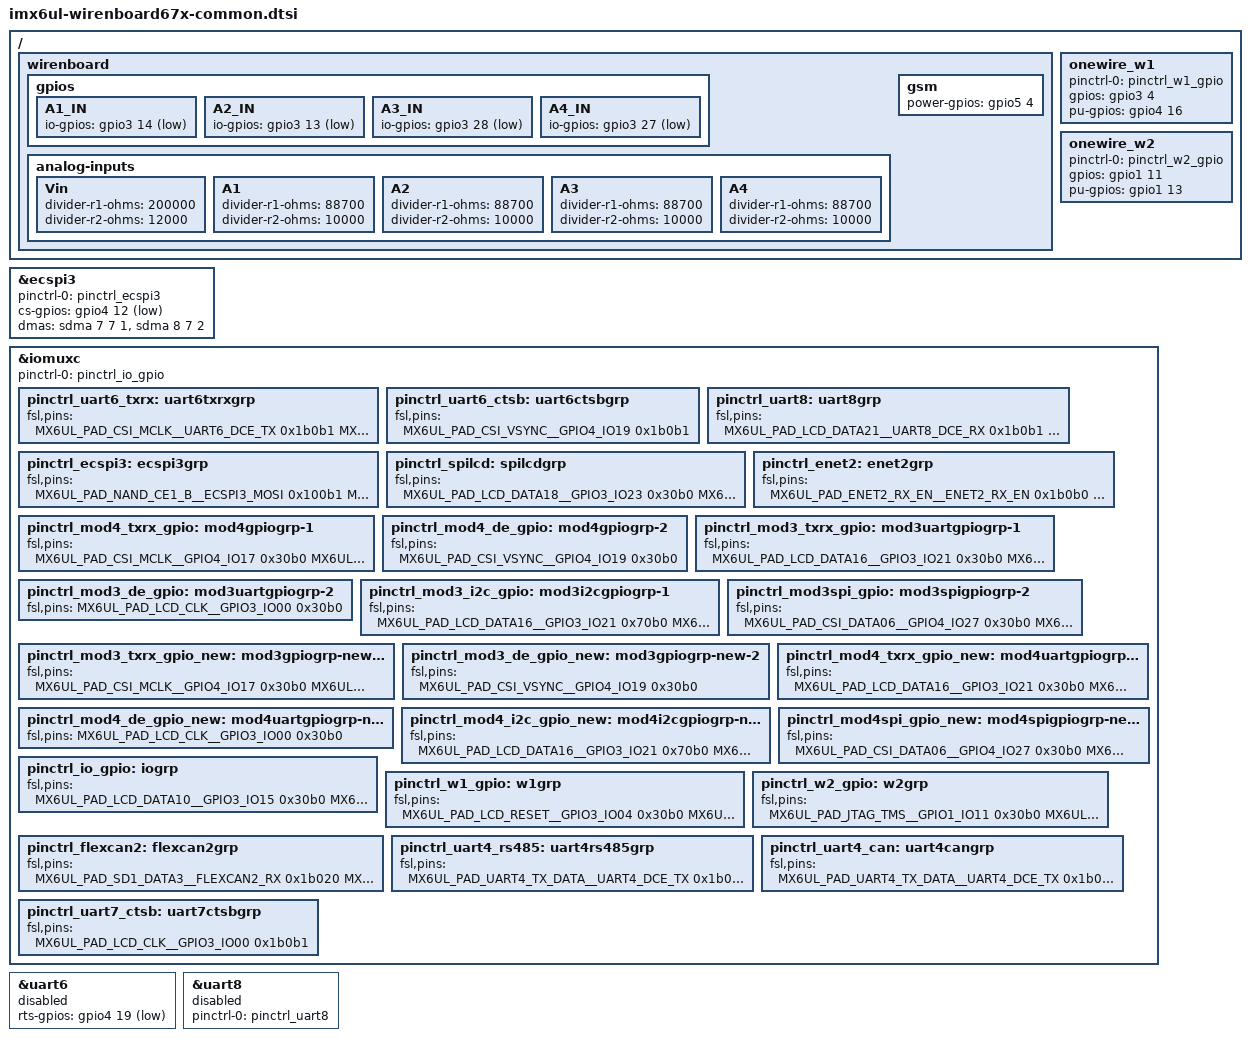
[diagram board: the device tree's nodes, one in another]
/*
 * Copyright 2020 Contactless Devices, LLC.
 *
 * The code contained herein is licensed under the GNU General Public
 * License. You may obtain a copy of the GNU General Public License
 * Version 2 or later at the following locations:
 *
 * http://www.opensource.org/licenses/gpl-license.html
 * http://www.gnu.org/copyleft/gpl.html
 */

#include "imx6ul-wirenboard6-common.dtsi"

/ {
	wirenboard {
			gpios {
				A1_IN {
					io-gpios = <&gpio3 14 1>; /* inverted */
				};

				A2_IN {
					io-gpios = <&gpio3 13 1>; /* inverted */
				};

				A3_IN {
					io-gpios = <&gpio3 28 1>; /* inverted */
				};

				A4_IN {
					io-gpios = <&gpio3 27 1>; /* inverted */
				};
			};

			analog-inputs {
				Vin {
					divider-r1-ohms = <200000>;
					divider-r2-ohms = <12000>;
				};

				A1 {
					divider-r1-ohms = <88700>;
					divider-r2-ohms = <10000>;
				};

				A2 {
					divider-r1-ohms = <88700>;
					divider-r2-ohms = <10000>;
				};

				A3 {
					divider-r1-ohms = <88700>;
					divider-r2-ohms = <10000>;
				};

				A4 {
					divider-r1-ohms = <88700>;
					divider-r2-ohms = <10000>;
				};
			};

			gsm {
				power-gpios = <&gpio5 4 0>;
			};
		};

	onewire_w1: onewire_w1 {
		pinctrl-0 = <&pinctrl_w1_gpio>;
		gpios = <&gpio3 4 0>;
		pu-gpios = <&gpio4 16 0>;
	};

	onewire_w2: onewire_w2 {
		pinctrl-0 = <&pinctrl_w2_gpio>;
		gpios = <&gpio1 11 0>;
		pu-gpios = <&gpio1 13 0>;
	};
};

&ecspi3 {
	pinctrl-names = "default";
	pinctrl-0 = <&pinctrl_ecspi3>;

	cs-gpios = <&gpio4 12 GPIO_ACTIVE_LOW>;

	dmas = <&sdma 7 7 1>, <&sdma 8 7 2>;
	dma-names = "rx", "tx";

	status = "okay";
};

&iomuxc {
	pinctrl-names = "default";
	pinctrl-0 = <&pinctrl_io_gpio>;

	pinctrl_uart6_txrx: uart6txrxgrp {
		fsl,pins = <
			MX6UL_PAD_CSI_MCLK__UART6_DCE_TX	0x1b0b1
			MX6UL_PAD_CSI_PIXCLK__UART6_DCE_RX	0x1b0b1
		>;
	};

	pinctrl_uart6_ctsb: uart6ctsbgrp {
		fsl,pins = <
			MX6UL_PAD_CSI_VSYNC__GPIO4_IO19	0x1b0b1
		>;
	};

	pinctrl_uart8: uart8grp {
		fsl,pins = <
			MX6UL_PAD_LCD_DATA21__UART8_DCE_RX   0x1b0b1
			MX6UL_PAD_LCD_DATA20__UART8_DCE_TX   0x1b0b1
		>;
	};

	pinctrl_ecspi3: ecspi3grp {
		fsl,pins = <
			MX6UL_PAD_NAND_CE1_B__ECSPI3_MOSI	0x100b1
			MX6UL_PAD_NAND_CLE__ECSPI3_MISO	0x100b1
			MX6UL_PAD_NAND_CE0_B__ECSPI3_SCLK	0x100b1
			MX6UL_PAD_NAND_READY_B__GPIO4_IO12	0x1b0b1 /* SSO */
		>;
	};

	pinctrl_spilcd: spilcdgrp {
		fsl,pins = <
			MX6UL_PAD_LCD_DATA18__GPIO3_IO23	0x30b0
			MX6UL_PAD_SNVS_TAMPER7__GPIO5_IO07	0x30b0
			MX6UL_PAD_SNVS_TAMPER8__GPIO5_IO08	0x30b0
			MX6UL_PAD_SNVS_TAMPER9__GPIO5_IO09	0x30b0
		>;
	};

	pinctrl_enet2: enet2grp {
		fsl,pins = <
			MX6UL_PAD_ENET2_RX_EN__ENET2_RX_EN	0x1b0b0
			MX6UL_PAD_ENET2_RX_DATA0__ENET2_RDATA00	0x1b0b0
			MX6UL_PAD_ENET2_RX_DATA1__ENET2_RDATA01	0x1b0b0
			MX6UL_PAD_ENET2_TX_EN__ENET2_TX_EN	0x1b0b0
			MX6UL_PAD_ENET2_TX_DATA0__ENET2_TDATA00	0x1b0b0
			MX6UL_PAD_ENET2_TX_DATA1__ENET2_TDATA01	0x1b0b0
			MX6UL_PAD_ENET2_TX_CLK__ENET2_REF_CLK2	0x4001b031
			MX6UL_PAD_ENET2_RX_ER__ENET2_RX_ER	0x1b0b0
		>;
	};

	/*
	 * Deprecated pinctrls for WB6.7.x mod3 and mod4 slots
	 * Providing compatibility with old wb-hwconf-manager versions, where mod3 and mod4 were changed places
	 * Actual wb6.7's mod3 is defined in dts as mod4 (and so on)
	 * Use new pinctrls (defined below) in new wb-hwconf-manager's versions!
	 */
	pinctrl_mod4_txrx_gpio: mod4gpiogrp-1 {
		fsl,pins = <
			MX6UL_PAD_CSI_MCLK__GPIO4_IO17		0x30b0
			MX6UL_PAD_CSI_PIXCLK__GPIO4_IO18	0x30b0
		>;
	};

	pinctrl_mod4_de_gpio: mod4gpiogrp-2 {
		fsl,pins = <
			MX6UL_PAD_CSI_VSYNC__GPIO4_IO19	0x30b0
		>;
	};

	pinctrl_mod3_txrx_gpio: mod3uartgpiogrp-1 {
		fsl,pins = <
			MX6UL_PAD_LCD_DATA16__GPIO3_IO21	0x30b0
			MX6UL_PAD_LCD_DATA17__GPIO3_IO22	0x30b0
		>;
	};

	pinctrl_mod3_de_gpio: mod3uartgpiogrp-2 {
		fsl,pins = <
			MX6UL_PAD_LCD_CLK__GPIO3_IO00	0x30b0
		>;
	};

	pinctrl_mod3_i2c_gpio: mod3i2cgpiogrp-1 {
		fsl,pins = <
			MX6UL_PAD_LCD_DATA16__GPIO3_IO21	0x70b0 /* SDA, 47K PU */
			MX6UL_PAD_LCD_DATA17__GPIO3_IO22	0x70b0 /* SCL, 47K PU */
		>;
	};

	pinctrl_mod3spi_gpio: mod3spigpiogrp-2 {
		fsl,pins = <
			MX6UL_PAD_CSI_DATA06__GPIO4_IO27	0x30b0
			MX6UL_PAD_CSI_DATA07__GPIO4_IO28	0x30b0
			MX6UL_PAD_CSI_DATA04__GPIO4_IO25	0x30b0
			MX6UL_PAD_CSI_DATA05__GPIO4_IO26	0x30b0
		>;
	};

	/*
	 * New pinctrls for WB6.7.x mod3 and mod4 slots
	 * Use these pinctrls by default in new wb-hwconf-manager's versions!
	 */
	pinctrl_mod3_txrx_gpio_new: mod3gpiogrp-new-1 {
		fsl,pins = <
			MX6UL_PAD_CSI_MCLK__GPIO4_IO17		0x30b0
			MX6UL_PAD_CSI_PIXCLK__GPIO4_IO18	0x30b0
		>;
	};

	pinctrl_mod3_de_gpio_new: mod3gpiogrp-new-2 {
		fsl,pins = <
			MX6UL_PAD_CSI_VSYNC__GPIO4_IO19	0x30b0
		>;
	};

	pinctrl_mod4_txrx_gpio_new: mod4uartgpiogrp-new-1 {
		fsl,pins = <
			MX6UL_PAD_LCD_DATA16__GPIO3_IO21	0x30b0
			MX6UL_PAD_LCD_DATA17__GPIO3_IO22	0x30b0
		>;
	};

	pinctrl_mod4_de_gpio_new: mod4uartgpiogrp-new-2 {
		fsl,pins = <
			MX6UL_PAD_LCD_CLK__GPIO3_IO00	0x30b0
		>;
	};

	pinctrl_mod4_i2c_gpio_new: mod4i2cgpiogrp-new-1 {
		fsl,pins = <
			MX6UL_PAD_LCD_DATA16__GPIO3_IO21	0x70b0 /* SDA, 47K PU */
			MX6UL_PAD_LCD_DATA17__GPIO3_IO22	0x70b0 /* SCL, 47K PU */
		>;
	};

	pinctrl_mod4spi_gpio_new: mod4spigpiogrp-new-2 {
		fsl,pins = <
			MX6UL_PAD_CSI_DATA06__GPIO4_IO27	0x30b0
			MX6UL_PAD_CSI_DATA07__GPIO4_IO28	0x30b0
			MX6UL_PAD_CSI_DATA04__GPIO4_IO25	0x30b0
			MX6UL_PAD_CSI_DATA05__GPIO4_IO26	0x30b0
		>;
	};

	pinctrl_io_gpio: iogrp {
		fsl,pins = <
			MX6UL_PAD_LCD_DATA10__GPIO3_IO15	0x30b0 /* FET1 */
			MX6UL_PAD_LCD_DATA11__GPIO3_IO16	0x30b0 /* FET2 */
			MX6UL_PAD_LCD_DATA12__GPIO3_IO17	0x30b0 /* FET3 */
			MX6UL_PAD_LCD_DATA13__GPIO3_IO18	0x30b0 /* FET4 */
			MX6UL_PAD_SNVS_TAMPER4__GPIO5_IO04	0x30b0 /* RESET_SIM900 (GSM_POWER) */
			MX6UL_PAD_LCD_DATA15__GPIO3_IO20	0x30b0 /* POWER_SIM900 (PWRKEY) */
			MX6UL_PAD_LCD_DATA14__GPIO3_IO19	0x30b0 /* STATUS SIM900 */
			MX6UL_PAD_LCD_DATA19__GPIO3_IO24	0x30b0 /* SIM select */
			MX6UL_PAD_UART1_CTS_B__GPIO1_IO18	0x70b0 /* Battery STAT1, pulled up */
			MX6UL_PAD_UART1_RTS_B__GPIO1_IO19	0x70b0 /* Battery STAT2, pulled up */
			MX6UL_PAD_JTAG_TDO__CCM_CLKO2	0xb0 /* 24MHz clock output */
			MX6UL_PAD_UART3_RTS_B__GPIO1_IO27	0x30b0 /* 5V enable */
			MX6UL_PAD_LCD_DATA04__GPIO3_IO09	0x30b0 /* V_OUT_ON */
			MX6UL_PAD_LCD_DATA03__GPIO3_IO08	0xb0b0 /* V_OUT_ST, 100K Ohm PU */
			MX6UL_PAD_CSI_DATA02__GPIO4_IO23	0x70b0 /* RS-485-1 failsafe bias, pulled up */

			MX6UL_PAD_LCD_DATA09__GPIO3_IO14 	0x30b0 /* IN1 */
			MX6UL_PAD_LCD_DATA08__GPIO3_IO13 	0x30b0 /* IN2 */
			MX6UL_PAD_LCD_DATA23__GPIO3_IO28 	0x30b0 /* IN3 */
			MX6UL_PAD_LCD_DATA22__GPIO3_IO27 	0x30b0 /* IN4 */

			MX6UL_PAD_SNVS_TAMPER0__GPIO5_IO00	0x30b0 /* TERM RS485-1, 47K Ohm PD */
			MX6UL_PAD_SNVS_TAMPER2__GPIO5_IO02 0x30b0 /* TERM RS485-2, 47K Ohm PD */

			MX6UL_PAD_JTAG_MOD__GPIO1_IO10		0x80000000 /* SPDIF_OUT connected to MODULE 2 TX PIN via 3K, must be high when i2c*/
		>;
	};

	pinctrl_w1_gpio: w1grp {
		fsl,pins = <
			MX6UL_PAD_LCD_RESET__GPIO3_IO04	0x30b0
			MX6UL_PAD_NAND_DQS__GPIO4_IO16	0x30b0
		>;
	};

	pinctrl_w2_gpio: w2grp {
		fsl,pins = <
			MX6UL_PAD_JTAG_TMS__GPIO1_IO11	0x30b0
			MX6UL_PAD_JTAG_TDI__GPIO1_IO13	0x30b0
		>;
	};

	pinctrl_flexcan2: flexcan2grp{
			fsl,pins = <
			MX6UL_PAD_SD1_DATA3__FLEXCAN2_RX	0x1b020
			MX6UL_PAD_SD1_DATA2__FLEXCAN2_TX	0x1b020
			MX6UL_PAD_UART4_TX_DATA__GPIO1_IO28	0xb0b0
			MX6UL_PAD_UART4_RX_DATA__GPIO1_IO29	0xb0b0
			MX6UL_PAD_LCD_ENABLE__GPIO3_IO01	0xb0b0
			MX6UL_PAD_LCD_HSYNC__GPIO3_IO02     0x30b0 /* RTS, 100K Ohm Pull Down */
			MX6UL_PAD_UART2_RTS_B__GPIO1_IO23   0xf0b0 /* CAN transceiver power, 22K Ohm Pull Up */
			MX6UL_PAD_CSI_HSYNC__GPIO4_IO20    0x30b0 /* RS-485-2 failsafe bias, 100K Ohm Pull Down  */
		>;
	};

	pinctrl_uart4_rs485: uart4rs485grp {
		fsl,pins = <
			MX6UL_PAD_UART4_TX_DATA__UART4_DCE_TX   0x1b0b1
			MX6UL_PAD_UART4_RX_DATA__UART4_DCE_RX   0x1b0b1
			MX6UL_PAD_LCD_HSYNC__UART4_DCE_CTS   0x1b0b1
			MX6UL_PAD_LCD_ENABLE__GPIO3_IO01   0xb0b0
			MX6UL_PAD_SD1_DATA3__GPIO2_IO21   0xb0b0
			MX6UL_PAD_SD1_DATA2__GPIO2_IO20   0xb0b0
			MX6UL_PAD_UART2_RTS_B__GPIO1_IO23   0x30b0 /* CAN transceiver power, 100K Ohm Pull Down */
			MX6UL_PAD_CSI_HSYNC__GPIO4_IO20    0x70b0 /* RS-485-2 failsafe bias, 47K Ohm Pull Up */
		>;
	};

	pinctrl_uart4_can: uart4cangrp {
		fsl,pins = <
			MX6UL_PAD_UART4_TX_DATA__UART4_DCE_TX   0x1b0b1
			MX6UL_PAD_LCD_ENABLE__UART4_DCE_RX   0x1b0b1
			MX6UL_PAD_UART4_RX_DATA__GPIO1_IO29   0xb0b0
			MX6UL_PAD_SD1_DATA3__GPIO2_IO21   0xb0b0
			MX6UL_PAD_SD1_DATA2__GPIO2_IO20   0xb0b0
			MX6UL_PAD_LCD_HSYNC__GPIO3_IO02     0x30b0 /* RTS, 100K Ohm Pull Down */
			MX6UL_PAD_UART2_RTS_B__GPIO1_IO23   0xf0b0 /* CAN transceiver power, 22K Ohm Pull Up */
			MX6UL_PAD_CSI_HSYNC__GPIO4_IO20    0x30b0 /* RS-485-2 failsafe bias, 100K Ohm Pull Down  */
		>;
	};

	pinctrl_uart7_ctsb: uart7ctsbgrp {
			fsl,pins = <
			MX6UL_PAD_LCD_CLK__GPIO3_IO00  0x1b0b1
		>;
	};
};


&uart6 { /* uart on mod3 */
	rts-gpios = <&gpio4 19 GPIO_ACTIVE_LOW>;
	status = "disabled";
};

&uart8 {
	pinctrl-names = "default";
	pinctrl-0 = <&pinctrl_uart8>;
	status = "disabled";
};
